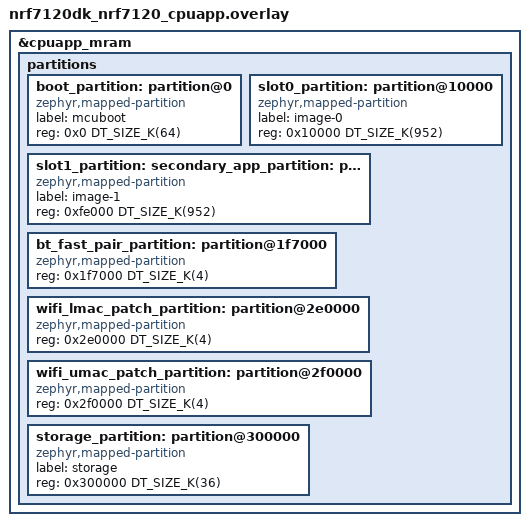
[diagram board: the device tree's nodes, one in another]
/*
 * Copyright (c) 2026 Nordic Semiconductor ASA
 *
 * SPDX-License-Identifier: LicenseRef-Nordic-5-Clause
 */

/*
 * Google Fast Pair needs a dedicated bt_fast_pair_partition to hold the
 * provisioned Model ID and Anti-Spoofing private key, which the default nRF7120
 * memory map (zephyr/dts/vendor/nordic/nrf7120_cpuapp_partition.dtsi) does not
 * define. This sample also runs in MCUboot direct-XIP mode, which requires two
 * equally sized, executable image slots. The layout is therefore redefined as
 * MCUboot + two image slots + the Fast Pair partition. The Wi-Fi LMAC/UMAC
 * ROM-patch partitions (0x2e0000 / 0x2f0000) and the "storage" partition (36K
 * at the end of MRAM) keep their default board addresses.
 */
&cpuapp_mram {
	/delete-node/ partitions;

	partitions {
		#address-cells = <1>;
		#size-cells = <1>;
		ranges;

		boot_partition: partition@0 {
			compatible = "zephyr,mapped-partition";
			label = "mcuboot";
			reg = <0x0 DT_SIZE_K(64)>;
		};

		slot0_partition: partition@10000 {
			compatible = "zephyr,mapped-partition";
			label = "image-0";
			reg = <0x10000 DT_SIZE_K(952)>;
		};

		slot1_partition: partition@fe000 {
			compatible = "zephyr,mapped-partition";
			label = "image-1";
			reg = <0xfe000 DT_SIZE_K(952)>;
		};

		bt_fast_pair_partition: partition@1f7000 {
			compatible = "zephyr,mapped-partition";
			reg = <0x1f7000 DT_SIZE_K(4)>;
		};

		wifi_lmac_patch_partition: partition@2e0000 {
			compatible = "zephyr,mapped-partition";
			reg = <0x2e0000 DT_SIZE_K(4)>;
		};

		wifi_umac_patch_partition: partition@2f0000 {
			compatible = "zephyr,mapped-partition";
			reg = <0x2f0000 DT_SIZE_K(4)>;
		};

		storage_partition: partition@300000 {
			compatible = "zephyr,mapped-partition";
			label = "storage";
			reg = <0x300000 DT_SIZE_K(36)>;
		};
	};
};

secondary_app_partition: &slot1_partition {};
